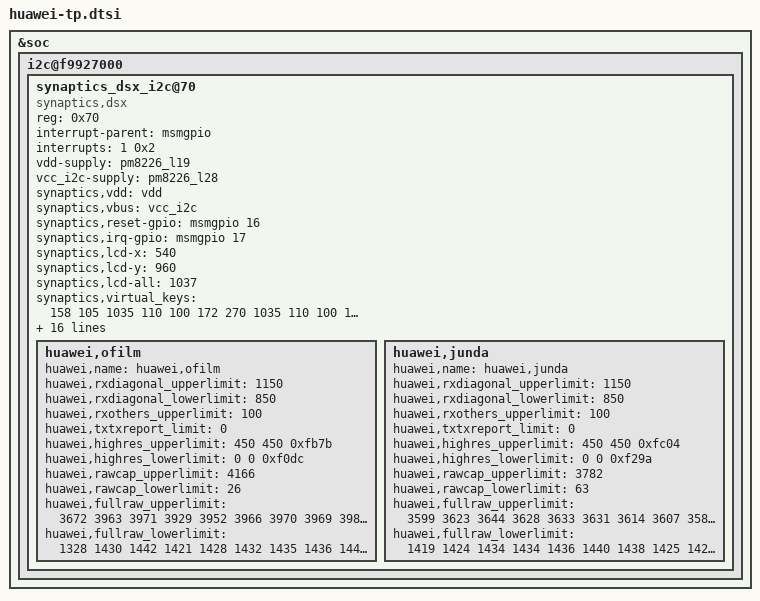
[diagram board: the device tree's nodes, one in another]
/*G730 use QHD*/
/*Add synaptics new driver "Synaptics DSX I2C V2.0"*/
&soc{
	i2c@f9927000 {
		status = "ok";
		synaptics_dsx_i2c@70 {
			compatible = "synaptics,dsx";
			reg = <0x70>;
			interrupt-parent = <&msmgpio>;
			interrupts = <1 0x2>;
			vdd-supply = <&pm8226_l19>;
			vcc_i2c-supply = <&pm8226_l28>;
			synaptics,vdd = "vdd";
			synaptics,vbus = "vcc_i2c";
			synaptics,reset-gpio = <&msmgpio 16 0x00>;
			synaptics,irq-gpio = <&msmgpio 17 0x00>;

			synaptics,lcd-x = <540>;
			synaptics,lcd-y = <960>;
			synaptics,lcd-all = <1037>;
			synaptics,virtual_keys = /* KeyCode CenterX CenterY Width Height */
				/* KEY_BACK */
				<158 105 1035 110 100
				/* KEY_HOMEPAGE instead of KEY_HOME(102) */
				172 270 1035 110 100
				/* KEY_MENU */
				139 435 1035 110 100>;

			/* SYNAPTICS_WAKE_UP_GESTURE_FLAG:'1'->enabled,'0'->disabled */
			synaptics,gesture_enabled = <0>;
			/* Gestures that supported:                           */
			/* bit0  Double tap                                        */
			/* bit1  Single finger slide from left to right     */
			/* bit2  Single finger slide from right to left     */
			/* bit3  Single finger slide from top to bottom  */
			/* bit4  Single finger slide from bottom to top  */
			/*delete the gesture of Double finger */
			/* bit5  Double finger slide from top to bottom */
			/* bit6  Single finger slide circle                     */
			/* bit7  Single finger write letter c                  */
			/* bit8  Single finger write letter e                  */
			/* bit9  Single finger write letter m                 */
			/* bit10 Single finger write letter w                 */
			/* bit11 Palm off screen                                */
			synaptics,easy_wakeup_supported_gestures = <0xFDF>;
			/*Defination of report key value  for different gestures*/
			synaptics,easy_wakeup_gesture_keys = 
			<	59 /*0.Double tap:KEY_F1*/
				60 /*1.Single finger slide from left to right*/
				61 /*2.Single finger slide from right to left:KEY_F3*/
				62 /*3.Single finger slide from top to bottom*/
				63 /*4.Single finger slide from bottom to top:KEY_F5*/
				64 /*5.Double finger slide from top to bottom*/
				65 /*6.Single finger slide circle:KEY_F7*/
				66 /*7.Single finger write letter c*/
				67 /*8.Single finger write letter e:KEY_F9*/
				68 /*9.Single finger write letter m*/
				87 /*10.Single finger write letter w:KEY_F11*/
				88 /*11.Palm off screen*/
			>;

			/* Double-tap-zone defined by huawei */
			/* Shielded area is:1cm left,1cm right,4cm up,2cm down */
			huawei,dtz_x0 = <78>;
			huawei,dtz_y0 = <318>;
			huawei,dtz_x1 = <462>;
			huawei,dtz_y1 = <801>;

			/* SYNAPTICS_GLOVE_FUNCTION_FLAG:'1'->enabled,'0'->disabled*/
			synaptics,glove_enabled = <0>;
			synaptics,fast_relax_gesture = <15>;
			synaptics,reset-on-status = <0>;
			synaptics,power-delay-ms = <160>;
			synaptics,reset-delay-ms = <100>;
			synaptics,reset-active-ms = <90>;
			synaptics,product_name = "g730L";
			
			/*capacitance self-adapt*/
			huawei,ofilm {
				huawei,name = "huawei,ofilm";
				huawei,rxdiagonal_upperlimit = <1150>;
				huawei,rxdiagonal_lowerlimit = <850>;
				huawei,rxothers_upperlimit = <100>;
				huawei,txtxreport_limit = <0>;
				huawei,highres_upperlimit = <450 450 0xfb7b>;/*0xfb7b==-1157*/
				huawei,highres_lowerlimit = <0 0 0xf0dc>;/*0xf0dc==-3876*/
				huawei,rawcap_upperlimit = <4166>;
				huawei,rawcap_lowerlimit = <26>;

				huawei,fullraw_upperlimit =
					<3672 3963 3971 3929 3952 3966 3970 3969 3987 3955 3991 3976 3974 4008 3908 3907 3914 3889 3901 3878 3869 3838 3866 3879 3857 3827 3831 225 
					3518 3810 3816 3808 3834 3819 3837 3808 3843 3796 3816 3833 3806 3803 3767 3760 3770 3749 3743 3719 3732 3760 3766 3718 3707 3693 3708 3749 
					3553 3833 3859 3857 3872 3823 3785 3778 3819 3799 3796 3809 3802 3795 3752 3743 3753 3753 3767 3739 3757 3736 3766 3743 3710 3697 3693 3767 
					3560 3820 3796 3781 3799 3791 3788 3782 3819 3775 3801 3803 3798 3791 3739 3735 3754 3757 3791 3759 3761 3763 3759 3703 3701 3708 3725 3780 
					3519 3778 3816 3785 3795 3802 3782 3767 3805 3774 3834 3837 3836 3817 3782 3770 3792 3768 3813 3754 3743 3718 3714 3710 3731 3745 3774 3683 
					3512 3796 3805 3809 3781 3789 3805 3747 3810 3768 3792 3805 3773 3766 3763 3753 3775 3756 3799 3808 3798 3732 3722 3717 3726 3752 3770 3696 
					3493 3796 3763 3770 3785 3795 3775 3777 3798 3753 3792 3822 3792 3768 3789 3787 3808 3813 3822 3799 3795 3701 3731 3707 3749 3773 3785 3764 
					3488 3805 3810 3794 3795 3791 3796 3763 3801 3745 3799 3805 3809 3803 3827 3813 3794 3764 3778 3760 3756 3732 3767 3739 3750 3767 3812 4015 
					3498 3789 3774 3778 3785 3767 3791 3775 3809 3747 3791 3791 3813 3813 3854 3833 3822 3764 3777 3782 3823 3788 3778 3724 3740 3768 3759 3715 
					3497 3753 3766 3754 3770 3787 3791 3770 3780 3742 3767 3810 3775 3770 3808 3778 3792 3794 3788 3799 3836 3782 3781 3738 3738 3746 3767 3672 
					3481 3738 3767 3760 3761 3777 3745 3770 3781 3739 3747 3780 3722 3739 3781 3789 3803 3767 3789 3831 3806 3775 3791 3759 3771 3774 3794 3705 
					3455 3777 3831 3801 3771 3738 3777 3838 3745 3761 3721 3738 3694 3705 3823 3789 3805 3781 3777 3798 3820 3802 3817 3787 3836 3841 3869 3908 
					3467 3726 3774 3802 3774 3725 3771 3816 3732 3703 3703 3700 3689 3687 3824 3819 3820 3812 3806 3816 3820 3801 3815 3816 3858 3852 3906 3973 
					3456 3746 3739 3731 3739 3729 3794 3725 3690 3663 3694 3690 3693 3693 3829 3840 3820 3787 3812 3795 3791 3789 3820 3774 3808 3850 3850 3836 
					3740 4015 4053 4055 4032 4020 3988 3964 3988 3953 3957 3966 3967 3985 4163 4062 4069 4064 4026 4016 4019 4029 4032 4008 4012 4025 3976 590>;

				huawei,fullraw_lowerlimit =
					<1328 1430 1442 1421 1428 1432 1435 1436 1447 1439 1440 1440 1445 1439 1412 1407 1398 1386 1413 1365 1413 1409 1415 1410 1413 1415 1416 26 
					1281 1375 1383 1371 1376 1377 1378 1377 1387 1378 1380 1378 1384 1376 1365 1361 1367 1356 1368 1317 1369 1363 1367 1364 1368 1368 1367 1389 
					1280 1375 1382 1370 1375 1377 1375 1374 1386 1376 1378 1378 1382 1374 1370 1359 1365 1353 1371 1317 1374 1368 1371 1367 1371 1374 1377 1401 
					1280 1373 1380 1367 1373 1375 1374 1371 1383 1374 1376 1379 1382 1374 1370 1368 1367 1356 1369 1317 1372 1365 1371 1367 1370 1372 1375 1397 
					1280 1375 1382 1370 1375 1375 1377 1374 1380 1374 1378 1380 1379 1374 1374 1368 1371 1358 1370 1318 1373 1370 1374 1369 1371 1374 1373 1348 
					1277 1373 1380 1367 1373 1374 1375 1373 1379 1373 1375 1377 1374 1370 1373 1371 1370 1359 1368 1320 1367 1364 1367 1365 1370 1377 1386 1355 
					1278 1372 1380 1368 1373 1374 1371 1371 1377 1371 1374 1376 1374 1370 1377 1373 1365 1358 1373 1323 1370 1365 1373 1371 1377 1382 1389 1372 
					1278 1374 1379 1370 1374 1374 1373 1371 1376 1371 1374 1375 1373 1370 1382 1375 1380 1375 1376 1323 1377 1374 1380 1376 1382 1386 1393 1481 
					1278 1374 1379 1370 1372 1370 1370 1365 1371 1366 1368 1370 1366 1364 1378 1373 1379 1374 1373 1357 1375 1371 1376 1370 1379 1382 1389 1372 
					1280 1376 1377 1373 1374 1371 1368 1367 1373 1363 1370 1368 1364 1363 1382 1379 1385 1380 1377 1374 1379 1376 1380 1375 1380 1384 1390 1357 
					1275 1372 1376 1370 1369 1368 1364 1362 1368 1360 1363 1363 1362 1356 1383 1376 1384 1379 1377 1375 1378 1373 1380 1373 1381 1383 1388 1357 
					1275 1373 1373 1370 1371 1368 1365 1364 1371 1362 1364 1366 1360 1359 1389 1382 1391 1386 1385 1379 1379 1375 1383 1377 1383 1385 1391 1420 
					1273 1363 1371 1361 1363 1364 1359 1358 1363 1355 1362 1356 1355 1356 1390 1383 1388 1385 1386 1382 1384 1380 1386 1381 1385 1388 1394 1437 
					1275 1367 1372 1366 1368 1365 1362 1358 1368 1357 1365 1362 1357 1357 1394 1387 1394 1392 1389 1384 1392 1387 1394 1388 1393 1396 1396 1409 
					1344 1434 1437 1433 1433 1435 1434 1430 1436 1428 1437 1433 1429 1430 1520 1494 1494 1488 1479 1475 1479 1473 1476 1470 1473 1473 1454 116>;
			};
			huawei,junda {
				huawei,name = "huawei,junda";
				huawei,rxdiagonal_upperlimit = <1150>;
				huawei,rxdiagonal_lowerlimit = <850>;
				huawei,rxothers_upperlimit = <100>;
				huawei,txtxreport_limit = <0>;
				huawei,highres_upperlimit = <450 450 0xfc04>;/*0xfc04==-1020*/
				huawei,highres_lowerlimit = <0 0 0xf29a>;/*0xf29a==-3430*/
				huawei,rawcap_upperlimit = <3782>;
				huawei,rawcap_lowerlimit = <63>;

				huawei,fullraw_upperlimit =
					<3599 3623 3644 3628 3633 3631 3614 3607 3589 3593 3589 3589 3570 3616 3341 3351 3330 3325 3327 3315 3306 3291 3291 3283 3287 3270 3238 252 
					3431 3452 3441 3434 3428 3421 3413 3413 3403 3397 3397 3406 3382 3383 3271 3278 3260 3255 3255 3243 3243 3220 3231 3224 3218 3213 3222 3245 
					3406 3432 3432 3418 3409 3404 3395 3392 3382 3379 3374 3375 3357 3350 3274 3277 3263 3257 3255 3245 3235 3218 3234 3231 3221 3215 3220 3253 
					3397 3423 3420 3407 3395 3392 3385 3382 3371 3368 3362 3354 3341 3330 3280 3281 3264 3264 3262 3252 3242 3221 3236 3232 3229 3222 3229 3259 
					3386 3417 3410 3399 3389 3382 3375 3375 3358 3357 3353 3340 3325 3315 3283 3287 3266 3266 3266 3257 3249 3228 3238 3236 3231 3229 3239 3200 
					3382 3409 3399 3386 3381 3375 3367 3365 3346 3337 3332 3320 3379 3592 3577 3560 3274 3586 3563 3558 3563 3543 3554 3533 3530 3536 3544 3505 
					3375 3396 3382 3378 3368 3365 3357 3353 3334 3330 3322 3313 3304 3285 3305 3304 3284 3277 3280 3269 3260 3248 3257 3252 3250 3246 3263 3236 
					3367 3389 3375 3364 3353 3353 3343 3339 3322 3326 3316 3308 3297 3458 3491 3460 3295 3491 3473 3467 3467 3441 3458 3434 3431 3438 3448 3564 
					3355 3383 3365 3360 3348 3344 3336 3329 3313 3312 3311 3297 3287 3271 3327 3325 3308 3306 3308 3292 3288 3273 3274 3277 3280 3274 3292 3259 
					3343 3372 3360 3351 3340 3334 3325 3320 3308 3301 3297 3290 3281 3256 3339 3330 3319 3319 3325 3312 3305 3288 3288 3288 3294 3288 3302 3257 
					3336 3365 3358 3346 3333 3329 3319 3312 3298 3295 3291 3284 3278 3245 3350 3344 3336 3336 3347 3332 3322 3306 3306 3302 3308 3305 3313 3270 
					3333 3361 3350 3336 3326 3326 3311 3306 3291 3288 3283 3277 3269 3242 3362 3353 3351 3346 3362 3350 3337 3327 3327 3325 3332 3325 3332 3369 
					3333 3358 3343 3333 3325 3322 3308 3305 3290 3288 3284 3281 3273 3242 3383 3372 3372 3369 3378 3362 3358 3348 3348 3346 3351 3350 3355 3425 
					3332 3362 3343 3337 3326 3325 3309 3313 3294 3291 3285 3284 3273 3245 3407 3399 3402 3393 3399 3385 3382 3372 3378 3376 3379 3376 3385 3441 
					3388 3414 3416 3385 3378 3374 3361 3358 3340 3340 3337 3330 3322 3285 3781 3756 3735 3691 3698 3682 3670 3649 3634 3626 3628 3613 3586 618>;

				huawei,fullraw_lowerlimit =
					<1419 1424 1434 1434 1436 1440 1438 1425 1424 1380 1343 1422 1295 1426 1230 1328 907 1322 1186 1318 1316 1307 1308 1308 1303 1043 1289 66 
					1349 1356 1361 1359 1357 1356 1356 1350 1349 1256 1187 1348 1153 1340 1226 1300 888 1293 1189 1290 1261 1263 1270 1268 1263 1023 1256 1238 
					1343 1351 1356 1352 1350 1348 1349 1341 1343 1245 1178 1339 1143 1327 1227 1301 889 1294 1293 1290 1287 1282 1280 1278 1279 1024 1280 1248 
					1341 1346 1352 1350 1347 1343 1346 1339 1335 1233 1170 1334 1134 1322 1226 1301 893 1298 1295 1293 1289 1281 1284 1282 1280 1026 1283 1250 
					1338 1342 1346 1344 1342 1339 1341 1332 1329 1224 1161 1326 1125 1316 1231 1300 900 1299 1295 1295 1293 1285 1287 1285 1282 1029 1286 1228 
					1333 1338 1343 1340 1337 1334 1335 1328 1322 1216 1152 1320 1117 1310 1236 1301 1013 1298 1298 1299 1296 1289 1290 1290 1285 1035 1291 1230 
					1329 1334 1337 1335 1332 1331 1331 1323 1318 1208 1144 1296 1112 1303 1241 1306 1307 1302 1302 1302 1300 1294 1295 1296 1292 1040 1297 1241 
					1323 1329 1332 1331 1328 1326 1327 1320 1313 1198 1138 834 782 1300 1244 1312 1013 1309 1308 1304 1305 1297 1300 1299 1299 1046 1305 1295 
					1322 1326 1327 1328 1325 1325 1323 1319 1311 1191 1134 783 705 1296 1282 1316 974 1314 1313 1309 1307 1301 1305 1306 1302 1054 1310 1251 
					1321 1325 1327 1326 1323 1321 1320 1315 1306 1184 1129 778 698 1290 1325 1324 972 1319 1319 1314 1315 1307 1313 1310 1306 1061 1315 1268 
					1320 1325 1328 1325 1323 1320 1319 1313 1304 1180 1125 774 695 1236 1294 1293 1270 1278 1287 1276 1280 1272 1269 1266 1275 1071 1282 1253 
					1320 1324 1325 1323 1320 1317 1317 1313 1302 1179 1122 773 696 1285 1337 1337 1334 1334 1334 1328 1329 1323 1323 1323 1322 1082 1319 1332 
					1318 1321 1325 1320 1268 1257 1262 1258 1245 1178 1122 771 695 1218 1297 1294 1293 1296 1296 1279 1284 1277 1277 1274 1275 1087 1278 1295 
					1319 1322 1325 1323 1320 1319 1319 1314 1302 1179 1121 770 694 1289 1350 1354 1351 1348 1348 1346 1346 1341 1341 1341 1340 1304 1346 1363 
					1314 1323 1342 1344 1335 1334 1335 1329 1322 1197 1131 776 700 1302 1494 1490 1483 1470 1470 1466 1461 1455 1435 1445 1439 1433 1430 204>;
			};
		};
	};
};

